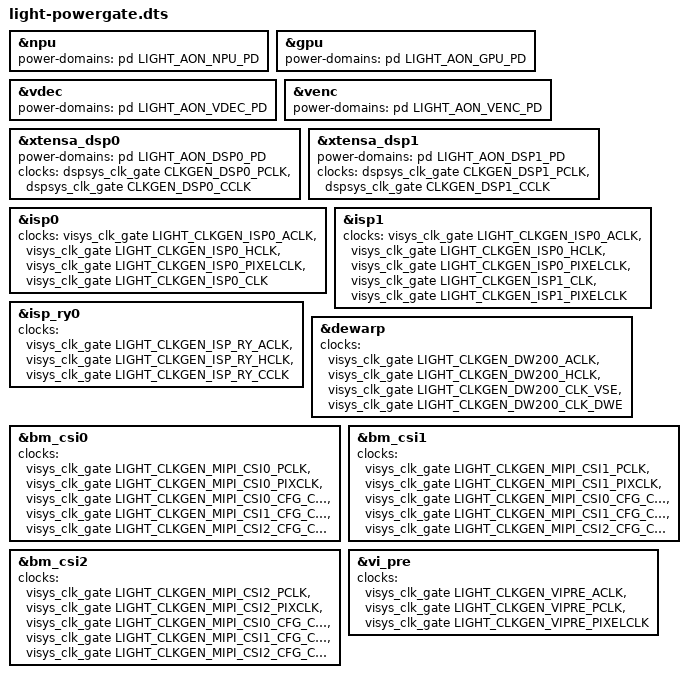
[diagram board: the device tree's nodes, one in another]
/* SPDX-License-Identifier: GPL-2.0 */
/*
 * Copyright (C) 2021 Alibaba Group Holding Limited.
 */

&npu {
	power-domains = <&pd LIGHT_AON_NPU_PD>;
};

&gpu {
	power-domains = <&pd LIGHT_AON_GPU_PD>;
};

&vdec {
	power-domains = <&pd LIGHT_AON_VDEC_PD>;
};

&venc {
	power-domains = <&pd LIGHT_AON_VENC_PD>;
};

&xtensa_dsp0 {
	power-domains = <&pd LIGHT_AON_DSP0_PD>;
	clocks = <&dspsys_clk_gate CLKGEN_DSP0_PCLK>, <&dspsys_clk_gate CLKGEN_DSP0_CCLK>;
	clock-names = "pclk", "cclk";
};

&xtensa_dsp1 {
	power-domains = <&pd LIGHT_AON_DSP1_PD>;
	clocks = <&dspsys_clk_gate CLKGEN_DSP1_PCLK>, <&dspsys_clk_gate CLKGEN_DSP1_CCLK>;
	clock-names = "pclk", "cclk";
};

&isp0 {
	clocks =  <&visys_clk_gate LIGHT_CLKGEN_ISP0_ACLK>,
	       <&visys_clk_gate LIGHT_CLKGEN_ISP0_HCLK>,
	       <&visys_clk_gate LIGHT_CLKGEN_ISP0_PIXELCLK>,
	       <&visys_clk_gate LIGHT_CLKGEN_ISP0_CLK>;
	clock-names = "aclk", "hclk", "isp0_pclk", "cclk";
};

&isp1 {
	clocks = <&visys_clk_gate LIGHT_CLKGEN_ISP0_ACLK>,
	       <&visys_clk_gate LIGHT_CLKGEN_ISP0_HCLK>,
	       <&visys_clk_gate LIGHT_CLKGEN_ISP0_PIXELCLK>,
	       <&visys_clk_gate LIGHT_CLKGEN_ISP1_CLK>,
	       <&visys_clk_gate LIGHT_CLKGEN_ISP1_PIXELCLK>;
	clock-names = "aclk", "hclk", "isp0_pclk", "cclk", "isp1_pclk";
};

&isp_ry0 {
	clocks = <&visys_clk_gate LIGHT_CLKGEN_ISP_RY_ACLK>,
	       <&visys_clk_gate LIGHT_CLKGEN_ISP_RY_HCLK>,
	        <&visys_clk_gate LIGHT_CLKGEN_ISP_RY_CCLK>;
	clock-names = "aclk", "hclk", "cclk";
};

&dewarp {
	clocks = <&visys_clk_gate LIGHT_CLKGEN_DW200_ACLK>,
		<&visys_clk_gate LIGHT_CLKGEN_DW200_HCLK>,
		<&visys_clk_gate LIGHT_CLKGEN_DW200_CLK_VSE>,
		<&visys_clk_gate LIGHT_CLKGEN_DW200_CLK_DWE>;
	clock-names = "aclk", "hclk", "vseclk", "dweclk";
};

&bm_csi0 { //CSI2
    clocks = <&visys_clk_gate LIGHT_CLKGEN_MIPI_CSI0_PCLK>,
		<&visys_clk_gate LIGHT_CLKGEN_MIPI_CSI0_PIXCLK>,
		<&visys_clk_gate LIGHT_CLKGEN_MIPI_CSI0_CFG_CLK>,
		<&visys_clk_gate LIGHT_CLKGEN_MIPI_CSI1_CFG_CLK>,
		<&visys_clk_gate LIGHT_CLKGEN_MIPI_CSI2_CFG_CLK>;
	clock-names = "pclk", "pixclk", "cfg_clk0", "cfg_clk1", "cfg_clk2";
};

&bm_csi1 { //CSI2X2_B
    clocks = <&visys_clk_gate LIGHT_CLKGEN_MIPI_CSI1_PCLK>,
		<&visys_clk_gate LIGHT_CLKGEN_MIPI_CSI1_PIXCLK>,
		<&visys_clk_gate LIGHT_CLKGEN_MIPI_CSI0_CFG_CLK>,
		<&visys_clk_gate LIGHT_CLKGEN_MIPI_CSI1_CFG_CLK>,
		<&visys_clk_gate LIGHT_CLKGEN_MIPI_CSI2_CFG_CLK>;
	clock-names = "pclk", "pixclk", "cfg_clk0", "cfg_clk1", "cfg_clk2";
};

&bm_csi2 { //CSI2X2_A
    clocks = <&visys_clk_gate LIGHT_CLKGEN_MIPI_CSI2_PCLK>,
		<&visys_clk_gate LIGHT_CLKGEN_MIPI_CSI2_PIXCLK>,
		<&visys_clk_gate LIGHT_CLKGEN_MIPI_CSI0_CFG_CLK>,
		<&visys_clk_gate LIGHT_CLKGEN_MIPI_CSI1_CFG_CLK>,
		<&visys_clk_gate LIGHT_CLKGEN_MIPI_CSI2_CFG_CLK>;
	clock-names = "pclk", "pixclk", "cfg_clk0", "cfg_clk1", "cfg_clk2";
};

&vi_pre {
    clocks = <&visys_clk_gate LIGHT_CLKGEN_VIPRE_ACLK>,
             <&visys_clk_gate LIGHT_CLKGEN_VIPRE_PCLK>,
             <&visys_clk_gate LIGHT_CLKGEN_VIPRE_PIXELCLK>;
    clock-names ="aclk", "pclk", "pixclk";
};

